# STM32F7x7 register map
File version: 1.4
CPU: CM7 r0p1, little endian, MPU, FPU, VTOR, 4 interrupt priority bits
Registers are 32-bit, read-write, reset 0x0 unless marked. A register's access mark holds for its fields unless they carry their own. Offsets are from the block's base; [hi:lo] are bit positions; {n}, {i} and the like mark numbered series.

## GPIOD — General-purpose I/Os
Base 0x40020C00
Same registers: GPIOC 0x40020800, GPIOE 0x40021000, GPIOF 0x40021400, GPIOG 0x40021800, GPIOH 0x40021C00, GPIOI 0x40022000, GPIOJ 0x40022400, GPIOK 0x40022800
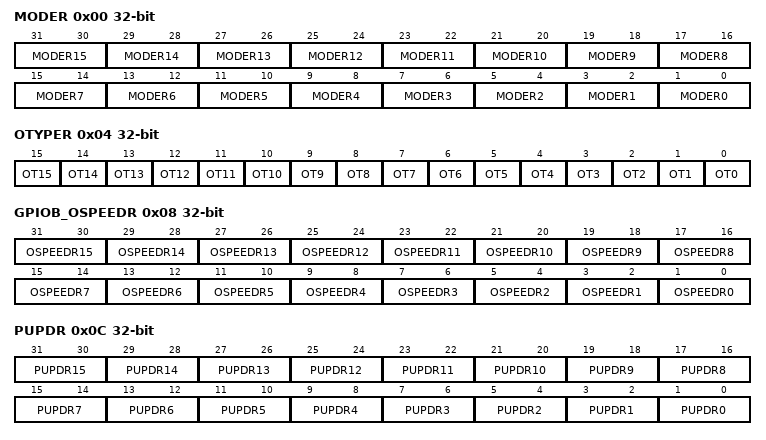
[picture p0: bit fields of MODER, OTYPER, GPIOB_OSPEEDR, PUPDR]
0x00 MODER — GPIO port mode register
  [2n+1:2n] MODER{n} (n=0..15) — Port x configuration bits (y = 0..15)
0x04 OTYPER — GPIO port output type register
  [n] OT{n} (n=0..15) — Port x configuration bits (y = 0..15)
0x08 GPIOB_OSPEEDR — GPIO port output speed register
  [2n+1:2n] OSPEEDR{n} (n=0..15) — Port x configuration bits (y = 0..15)
0x0C PUPDR — GPIO port pull-up/pull-down register
  [2n+1:2n] PUPDR{n} (n=0..15) — Port x configuration bits (y = 0..15)
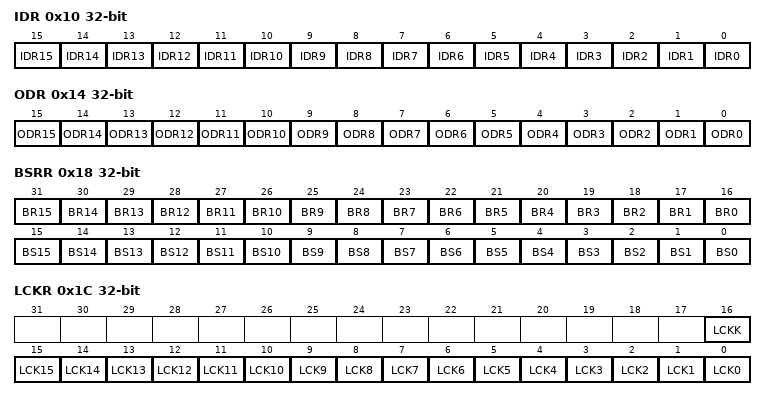
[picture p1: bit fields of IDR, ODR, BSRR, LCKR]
0x10 IDR ro — GPIO port input data register
  [n] IDR{n} (n=0..15) — Port input data (y = 0..15)
0x14 ODR — GPIO port output data register
  [n] ODR{n} (n=0..15) — Port output data (y = 0..15)
0x18 BSRR wo — GPIO port bit set/reset register
  [n+16] BR{n} (n=1..15) — Port x reset bit y (y = 0..15)
  [16] BR0 — Port x set bit y (y= 0..15)
  [n] BS{n} (n=0..15) — Port x set bit y (y= 0..15)
0x1C LCKR — GPIO port configuration lock register
  [16] LCKK — Port x lock bit y (y= 0..15)
  [n] LCK{n} (n=0..15) — Port x lock bit y (y= 0..15)
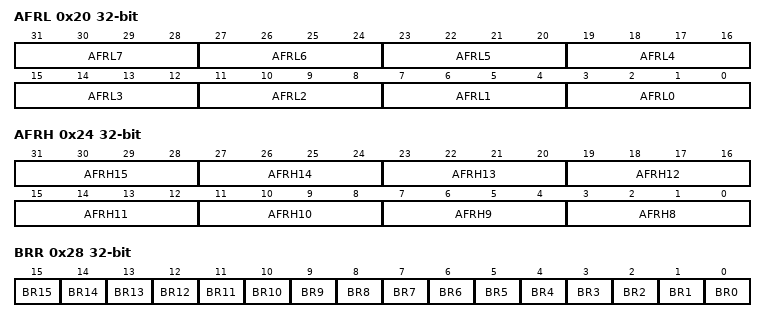
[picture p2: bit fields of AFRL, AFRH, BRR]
0x20 AFRL — GPIO alternate function lowregister
  [4n+3:4n] AFRL{n} (n=0..7) — Alternate function selection for port x bit y (y = 0..7)
0x24 AFRH — GPIO alternate function high register
  [4n-29:4n-32] AFRH{n} (n=8..15) — Alternate function selection for port x bit y (y = 8..15)
0x28 BRR — GPIO port bit reset register
  [n] BR{n} (n=0..15) — Port D Reset bit {n}

## GPIOB — General-purpose I/Os
Base 0x40020400
Registers as GPIOD, without GPIOB_OSPEEDR; these are added or differ:
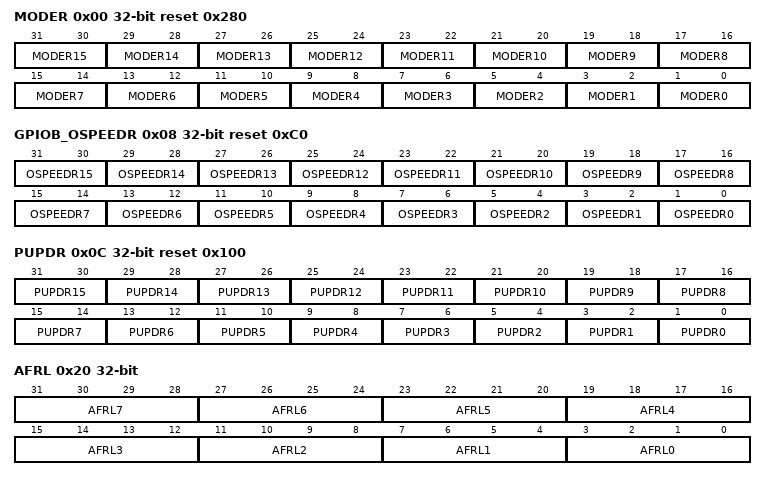
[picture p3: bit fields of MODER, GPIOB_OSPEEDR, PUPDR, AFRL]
0x00 MODER reset 0x280 — GPIO port mode register
  [2n+1:2n] MODER{n} (n=0..15) — Port x configuration bits (y = 0..15)
0x08 GPIOB_OSPEEDR reset 0xC0 — GPIO port output speed register
  [2n+1:2n] OSPEEDR{n} (n=0..15) — Port x configuration bits (y = 0..15)
0x0C PUPDR reset 0x100 — GPIO port pull-up/pull-down register
  [2n+1:2n] PUPDR{n} (n=0..15) — Port x configuration bits (y = 0..15)
0x20 AFRL — GPIO alternate function low register
  [4n+3:4n] AFRL{n} (n=0..7) — Alternate function selection for port x bit y (y = 0..7)
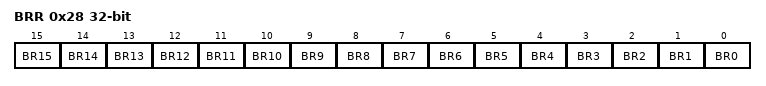
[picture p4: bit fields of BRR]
0x28 BRR — GPIO port bit reset register
  [n] BR{n} (n=0..15) — Port B Reset bit {n}

## GPIOA — General-purpose I/Os
Base 0x40020000
Registers as GPIOB, without GPIOB_OSPEEDR; these are added or differ:
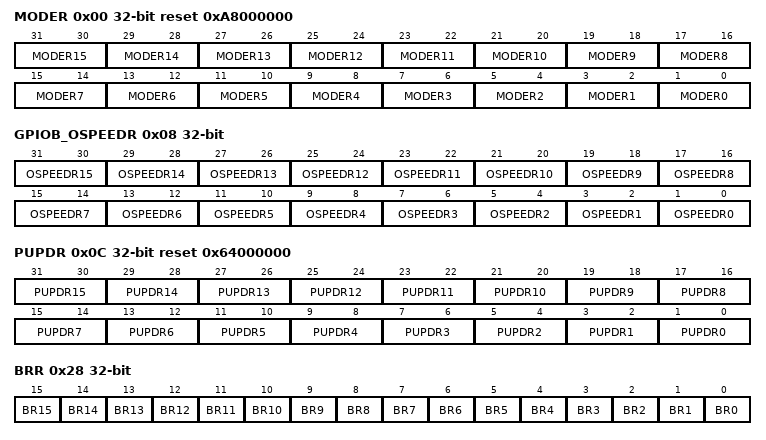
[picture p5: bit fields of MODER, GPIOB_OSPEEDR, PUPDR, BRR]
0x00 MODER reset 0xA8000000 — GPIO port mode register
  [2n+1:2n] MODER{n} (n=0..15) — Port x configuration bits (y = 0..15)
0x08 GPIOB_OSPEEDR — GPIO port output speed register
  [2n+1:2n] OSPEEDR{n} (n=0..15) — Port x configuration bits (y = 0..15)
0x0C PUPDR reset 0x64000000 — GPIO port pull-up/pull-down register
  [2n+1:2n] PUPDR{n} (n=0..15) — Port x configuration bits (y = 0..15)
0x28 BRR — GPIO port bit reset register
  [n] BR{n} (n=0..15) — Port A Reset bit {n}

## SYSCFG — System configuration controller
Base 0x40013800
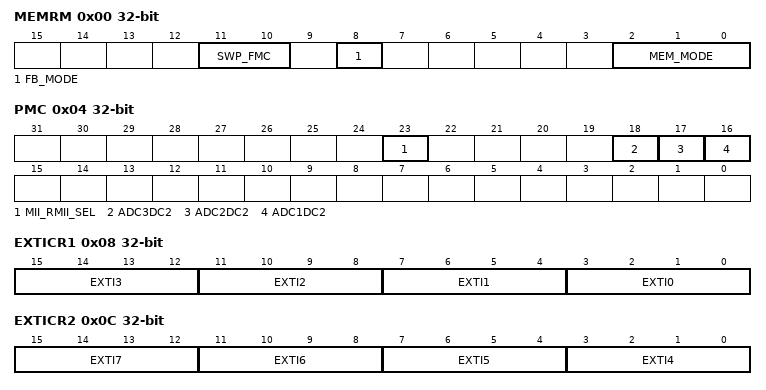
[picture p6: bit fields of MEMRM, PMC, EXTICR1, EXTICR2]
0x00 MEMRM — memory remap register
  [11:10] SWP_FMC — FMC memory mapping swap
  [8] FB_MODE — Flash bank mode selection
  [2:0] MEM_MODE — Memory mapping selection
0x04 PMC — peripheral mode configuration register
  [23] MII_RMII_SEL — Ethernet PHY interface selection
  [18] ADC3DC2
  [17] ADC2DC2
  [16] ADC1DC2
0x08 EXTICR1 — external interrupt configuration register 1
  [4n+3:4n] EXTI{n} (n=0..3) — EXTI x configuration (x = 0 to 3)
0x0C EXTICR2 — external interrupt configuration register 2
  [4n-13:4n-16] EXTI{n} (n=4..7) — EXTI x configuration (x = 4 to 7)
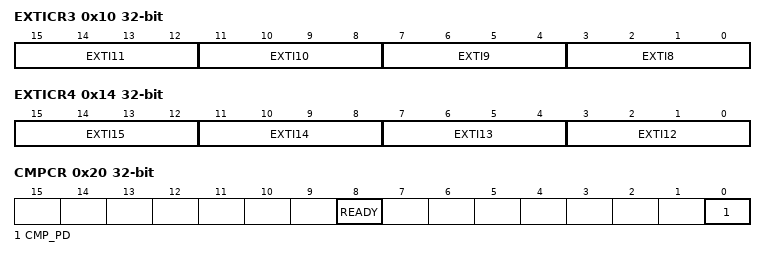
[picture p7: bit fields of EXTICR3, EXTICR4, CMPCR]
0x10 EXTICR3 — external interrupt configuration register 3
  [15:12] EXTI11 — EXTI x configuration (x = 8 to 11)
  [11:8] EXTI10
  [7:4] EXTI9 — EXTI x configuration (x = 8 to 11)
  [3:0] EXTI8 — EXTI x configuration (x = 8 to 11)
0x14 EXTICR4 — external interrupt configuration register 4
  [4n-45:4n-48] EXTI{n} (n=12..15) — EXTI x configuration (x = 12 to 15)
0x20 CMPCR ro — Compensation cell control register
  [8] READY
  [0] CMP_PD — Compensation cell power-down
